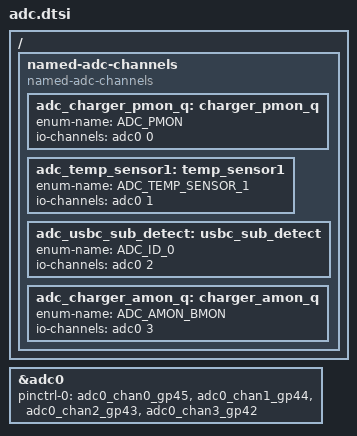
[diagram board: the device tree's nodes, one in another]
/* Copyright 2025 The ChromiumOS Authors
 * Use of this source code is governed by a BSD-style license that can be
 * found in the LICENSE file.
 */

/ {
	named-adc-channels {
		compatible = "named-adc-channels";

		adc_charger_pmon_q: charger_pmon_q {
			enum-name = "ADC_PMON";
			io-channels = <&adc0 0>;
		};
		adc_temp_sensor1: temp_sensor1 {
			enum-name = "ADC_TEMP_SENSOR_1";
			io-channels = <&adc0 1>;
		};
		adc_usbc_sub_detect: usbc_sub_detect {
			enum-name = "ADC_ID_0";
			io-channels = <&adc0 2>;
		};
		adc_charger_amon_q: charger_amon_q {
			enum-name = "ADC_AMON_BMON";
			io-channels = <&adc0 3>;
		};
	};
};

&adc0 {
	status = "okay";
	pinctrl-0 = <&adc0_chan0_gp45
		     &adc0_chan1_gp44
		     &adc0_chan2_gp43
		     &adc0_chan3_gp42>;
	pinctrl-names = "default";
};
